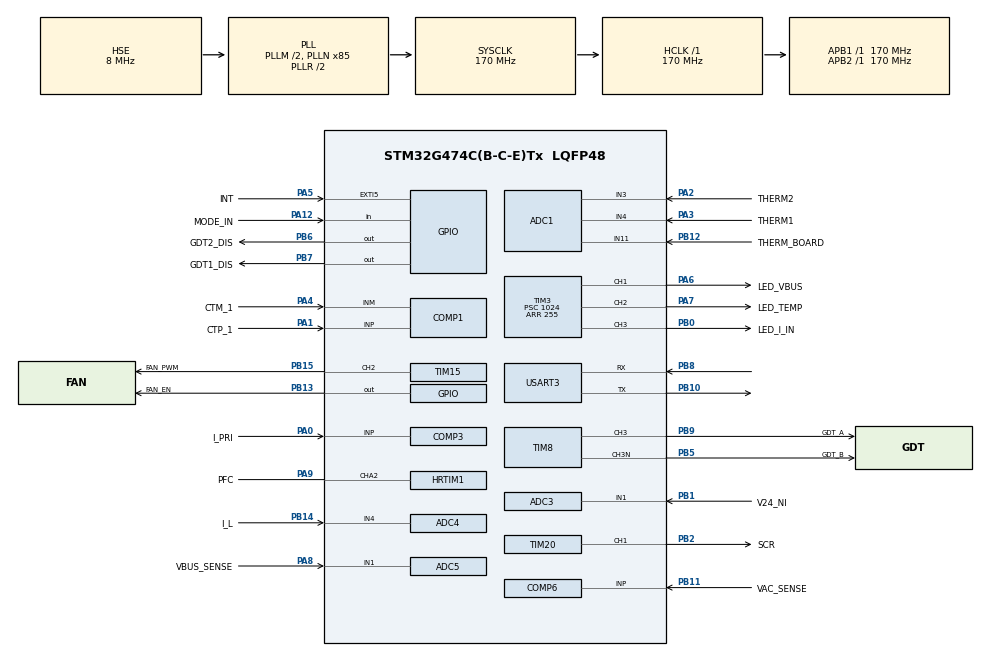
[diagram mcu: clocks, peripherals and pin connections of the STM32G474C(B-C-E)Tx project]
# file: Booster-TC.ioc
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ADC1.Channel-1\#ChannelRegularConversion=ADC_CHANNEL_3
ADC1.Channel-2\#ChannelRegularConversion=ADC_CHANNEL_4
ADC1.Channel-3\#ChannelRegularConversion=ADC_CHANNEL_11
ADC1.Channel-4\#ChannelRegularConversion=ADC_CHANNEL_VREFINT
ADC1.ClockPrescaler=ADC_CLOCK_SYNC_PCLK_DIV4
ADC1.EOCSelection=ADC_EOC_SEQ_CONV
ADC1.ExternalTrigConv=ADC_EXTERNALTRIG_T6_TRGO
ADC1.Mode=ADC_MODE_INDEPENDENT
ADC1.NbrOfConversion=4
ADC1.NbrOfConversionFlag=1
ADC1.OffsetNumber-1\#ChannelRegularConversion=ADC_OFFSET_NONE
ADC1.OffsetNumber-2\#ChannelRegularConversion=ADC_OFFSET_NONE
ADC1.OffsetNumber-3\#ChannelRegularConversion=ADC_OFFSET_NONE
ADC1.OffsetNumber-4\#ChannelRegularConversion=ADC_OFFSET_NONE
ADC1.OversamplingMode=ENABLE
ADC1.Rank-1\#ChannelRegularConversion=1
ADC1.Rank-2\#ChannelRegularConversion=2
ADC1.Rank-3\#ChannelRegularConversion=3
ADC1.Rank-4\#ChannelRegularConversion=4
ADC1.Ratio=ADC_OVERSAMPLING_RATIO_2
ADC1.RightBitShift=ADC_RIGHTBITSHIFT_1
ADC1.SamplingTime-1\#ChannelRegularConversion=ADC_SAMPLETIME_2CYCLES_5
ADC1.SamplingTime-2\#ChannelRegularConversion=ADC_SAMPLETIME_2CYCLES_5
ADC1.SamplingTime-3\#ChannelRegularConversion=ADC_SAMPLETIME_2CYCLES_5
ADC1.SamplingTime-4\#ChannelRegularConversion=ADC_SAMPLETIME_2CYCLES_5
ADC1.master=1
ADC2.Channel-2\#ChannelRegularConversion=ADC_CHANNEL_14
ADC2.ExternalTrigConv=ADC_EXTERNALTRIG_HRTIM_TRG3
ADC2.NbrOfConversionFlag=1
ADC2.OffsetNumber-2\#ChannelRegularConversion=ADC_OFFSET_NONE
ADC2.Rank-2\#ChannelRegularConversion=1
ADC2.SamplingTime-2\#ChannelRegularConversion=ADC_SAMPLETIME_2CYCLES_5
ADC3.Channel-1\#ChannelRegularConversion=ADC_CHANNEL_1
ADC3.NbrOfConversion=1
ADC3.NbrOfConversionFlag=1
ADC3.OffsetNumber-1\#ChannelRegularConversion=ADC_OFFSET_NONE
ADC3.Rank-1\#ChannelRegularConversion=1
ADC3.SamplingTime-1\#ChannelRegularConversion=ADC_SAMPLETIME_2CYCLES_5
ADC3.master=1
ADC4.Channel-1\#ChannelRegularConversion=ADC_CHANNEL_4
ADC4.ExternalTrigConv=ADC_EXTERNALTRIG_HRTIM_TRG3
ADC4.NbrOfConversionFlag=1
ADC4.OffsetNumber-1\#ChannelRegularConversion=ADC_OFFSET_NONE
ADC4.OversamplingMode=ENABLE
ADC4.Rank-1\#ChannelRegularConversion=1
ADC4.RightBitShift=ADC_RIGHTBITSHIFT_1
ADC4.SamplingTime-1\#ChannelRegularConversion=ADC_SAMPLETIME_2CYCLES_5
ADC5.Channel-1\#ChannelRegularConversion=ADC_CHANNEL_1
ADC5.ExternalTrigConv=ADC_EXTERNALTRIG_HRTIM_TRG1
ADC5.NbrOfConversionFlag=1
ADC5.OffsetNumber-1\#ChannelRegularConversion=ADC_OFFSET_NONE
ADC5.Rank-1\#ChannelRegularConversion=1
ADC5.SamplingTime-1\#ChannelRegularConversion=ADC_SAMPLETIME_2CYCLES_5
COMP1.TriggerMode=COMP_TRIGGERMODE_NONE
COMP3.TriggerMode=COMP_TRIGGERMODE_IT_RISING_FALLING
COMP6.Hysteresis=COMP_HYSTERESIS_NONE
COMP6.TriggerMode=COMP_TRIGGERMODE_IT_FALLING
DAC4.DAC_Channel-DAC_OUT2_Int=DAC_CHANNEL_2
Dma.ADC1.0.Direction=DMA_PERIPH_TO_MEMORY
Dma.ADC1.0.EventEnable=DISABLE
Dma.ADC1.0.Instance=DMA1_Channel1
Dma.ADC1.0.MemDataAlignment=DMA_MDATAALIGN_HALFWORD
Dma.ADC1.0.MemInc=DMA_MINC_ENABLE
Dma.ADC1.0.Mode=DMA_NORMAL
Dma.ADC1.0.PeriphDataAlignment=DMA_PDATAALIGN_HALFWORD
Dma.ADC1.0.PeriphInc=DMA_PINC_DISABLE
Dma.ADC1.0.Polarity=HAL_DMAMUX_REQ_GEN_RISING
Dma.ADC1.0.Priority=DMA_PRIORITY_LOW
Dma.ADC1.0.RequestNumber=1
Dma.ADC1.0.SignalID=NONE
Dma.ADC1.0.SyncEnable=DISABLE
Dma.ADC1.0.SyncPolarity=HAL_DMAMUX_SYNC_NO_EVENT
Dma.ADC1.0.SyncRequestNumber=1
Dma.ADC1.0.SyncSignalID=NONE
Dma.ADC2.1.Direction=DMA_PERIPH_TO_MEMORY
Dma.ADC2.1.EventEnable=DISABLE
Dma.ADC2.1.Instance=DMA2_Channel1
Dma.ADC2.1.MemDataAlignment=DMA_MDATAALIGN_HALFWORD
Dma.ADC2.1.MemInc=DMA_MINC_ENABLE
Dma.ADC2.1.Mode=DMA_NORMAL
Dma.ADC2.1.PeriphDataAlignment=DMA_PDATAALIGN_HALFWORD
Dma.ADC2.1.PeriphInc=DMA_PINC_DISABLE
Dma.ADC2.1.Polarity=HAL_DMAMUX_REQ_GEN_RISING
Dma.ADC2.1.Priority=DMA_PRIORITY_VERY_HIGH
Dma.ADC2.1.RequestNumber=1
Dma.ADC2.1.SignalID=NONE
Dma.ADC2.1.SyncEnable=DISABLE
Dma.ADC2.1.SyncPolarity=HAL_DMAMUX_SYNC_NO_EVENT
Dma.ADC2.1.SyncRequestNumber=1
Dma.ADC2.1.SyncSignalID=NONE
Dma.ADC4.2.Direction=DMA_PERIPH_TO_MEMORY
Dma.ADC4.2.EventEnable=DISABLE
Dma.ADC4.2.Instance=DMA2_Channel2
Dma.ADC4.2.MemDataAlignment=DMA_MDATAALIGN_HALFWORD
Dma.ADC4.2.MemInc=DMA_MINC_ENABLE
Dma.ADC4.2.Mode=DMA_NORMAL
Dma.ADC4.2.PeriphDataAlignment=DMA_PDATAALIGN_HALFWORD
Dma.ADC4.2.PeriphInc=DMA_PINC_DISABLE
Dma.ADC4.2.Polarity=HAL_DMAMUX_REQ_GEN_RISING
Dma.ADC4.2.Priority=DMA_PRIORITY_VERY_HIGH
Dma.ADC4.2.RequestNumber=1
Dma.ADC4.2.SignalID=NONE
Dma.ADC4.2.SyncEnable=DISABLE
Dma.ADC4.2.SyncPolarity=HAL_DMAMUX_SYNC_NO_EVENT
Dma.ADC4.2.SyncRequestNumber=1
Dma.ADC4.2.SyncSignalID=NONE
Dma.ADC5.3.Direction=DMA_PERIPH_TO_MEMORY
Dma.ADC5.3.EventEnable=DISABLE
Dma.ADC5.3.Instance=DMA1_Channel2
Dma.ADC5.3.MemDataAlignment=DMA_MDATAALIGN_HALFWORD
Dma.ADC5.3.MemInc=DMA_MINC_ENABLE
Dma.ADC5.3.Mode=DMA_NORMAL
Dma.ADC5.3.PeriphDataAlignment=DMA_PDATAALIGN_HALFWORD
Dma.ADC5.3.PeriphInc=DMA_PINC_DISABLE
Dma.ADC5.3.Polarity=HAL_DMAMUX_REQ_GEN_RISING
Dma.ADC5.3.Priority=DMA_PRIORITY_LOW
Dma.ADC5.3.RequestNumber=1
Dma.ADC5.3.SignalID=NONE
Dma.ADC5.3.SyncEnable=DISABLE
Dma.ADC5.3.SyncPolarity=HAL_DMAMUX_SYNC_NO_EVENT
Dma.ADC5.3.SyncRequestNumber=1
Dma.ADC5.3.SyncSignalID=NONE
Dma.Request0=ADC1
Dma.Request1=ADC2
Dma.Request2=ADC4
Dma.Request3=ADC5
HRTIM1.ADCTrigger1_Source1=HRTIM_ADCTRIGGEREVENT13_TIMERD_PERIOD
HRTIM1.ADCTrigger3_Source1=HRTIM_ADCTRIGGEREVENT13_TIMERA_CMP3
HRTIM1.ADCTrigger_Id1=HRTIM_ADCTRIGGER_1
HRTIM1.ADCTrigger_Id2=__NULL
HRTIM1.ADCTrigger_Id3=HRTIM_ADCTRIGGER_3
HRTIM1.CompareUnit1-Output_TA2=HRTIM_COMPAREUNIT_1
HRTIM1.CompareUnit2-Output_TA2=__NULL
HRTIM1.CompareUnit3-Output_TA2=HRTIM_COMPAREUNIT_3
HRTIM1.Event_EEV1=__NULL
HRTIM1.Event_EEV2=__NULL
HRTIM1.Event_EEV3=__NULL
HRTIM1.Event_EEV4=__NULL
HRTIM1.Event_EEV5=HRTIM_EVENT_5
HRTIM1.Event_EEV7=__NULL
HRTIM1.FastMode_EEV5=HRTIM_EVENTFASTMODE_ENABLE
HRTIM1.Fault_Line1=__NULL
HRTIM1.NumberADCTriggerSource1=1
HRTIM1.NumberADCTriggerSource3=1
HRTIM1.NumberFaultEnable-Output_TA2=0
HRTIM1.NumberResetSource2-Output_TA2=2
HRTIM1.NumberSetSource2-Output_TA2=1
HRTIM1.ORingUpdateSource_ADCTrigger1=HRTIM_ADCTRIGGERUPDATE_TIMER_D
HRTIM1.Periode_TA=0xB115
HRTIM1.Periode_TD=0xDD5A
HRTIM1.PrescalerRatio_TA=HRTIM_PRESCALERRATIO_MUL16
HRTIM1.PrescalerRatio_TD=HRTIM_PRESCALERRATIO_MUL2
HRTIM1.ResetOutput2_Source1-Output_TA2=HRTIM_OUTPUTRESET_TIMCMP1
HRTIM1.ResetOutput2_Source2-Output_TA2=HRTIM_OUTPUTSET_EEV_5
HRTIM1.SetOutput2_Source1-Output_TA2=HRTIM_OUTPUTSET_TIMPER
HRTIM1.Source_EEV5=HRTIM_EEV5SRC_COMP7_OUT
HRTIM1.UpDownMode-Output_TA2=HRTIM_TIMERUPDOWNMODE_UP
Mcu.Family=STM32G4
Mcu.Name=STM32G474C(B-C-E)Tx
Mcu.Package=LQFP48
NVIC.ADC1_2_IRQn=true\:0\:0\:false\:false\:false\:true\:true\:true
NVIC.ADC4_IRQn=true\:0\:0\:false\:false\:false\:true\:true\:true
NVIC.ADC5_IRQn=true\:0\:0\:false\:false\:false\:true\:true\:true
NVIC.COMP1_2_3_IRQn=true\:0\:0\:false\:false\:true\:false\:true\:true
NVIC.COMP4_5_6_IRQn=true\:0\:0\:false\:false\:true\:false\:true\:true
NVIC.DMA1_Channel1_IRQn=true\:0\:0\:false\:false\:true\:false\:true\:true
NVIC.DMA1_Channel2_IRQn=true\:0\:0\:false\:false\:true\:false\:true\:true
NVIC.DMA2_Channel1_IRQn=true\:0\:0\:false\:false\:true\:false\:true\:true
NVIC.DMA2_Channel2_IRQn=true\:0\:0\:false\:false\:true\:false\:true\:true
NVIC.EXTI9_5_IRQn=true\:0\:0\:false\:false\:true\:true\:true\:true
NVIC.FMAC_IRQn=true\:0\:0\:false\:false\:true\:true\:true\:true
NVIC.PriorityGroup=NVIC_PRIORITYGROUP_4
NVIC.TIM1_CC_IRQn=true\:0\:0\:false\:false\:false\:true\:true\:true
NVIC.TIM1_TRG_COM_TIM17_IRQn=true\:0\:0\:false\:false\:true\:true\:true\:true
NVIC.TIM6_DAC_IRQn=true\:0\:0\:false\:false\:false\:true\:true\:true
NVIC.TIM7_DAC_IRQn=true\:0\:0\:false\:false\:false\:true\:true\:true
PA0.GPIO_Label=I_PRI
PA0.Mode=INP
PA0.Signal=COMP3_INP
PA1.GPIO_Label=CTP_1
PA1.Mode=INP
PA1.Signal=COMP1_INP
PA12.GPIO_Label=MODE_IN
PA12.GPIO_PuPd=GPIO_NOPULL
PA12.Signal=GPIO_Input
PA13.GPIO_Label=TMS
PA13.Mode=JTAG_4_pins
PA13.Signal=SYS_JTMS-SWDIO
PA14.GPIO_Label=TCK
PA14.Mode=JTAG_4_pins
PA14.Signal=SYS_JTCK-SWCLK
PA15.Mode=JTAG_4_pins
PA15.Signal=SYS_JTDI
PA2.GPIO_Label=THERM2
PA2.Mode=IN3-Single-Ended
PA2.Signal=ADC1_IN3
PA3.GPIO_Label=THERM1
PA3.Mode=IN4-Single-Ended
PA3.Signal=ADC1_IN4
PA4.GPIO_Label=CTM_1
PA4.Mode=INM
PA4.Signal=COMP1_INM
PA5.GPIO_Label=INT
PA5.GPIO_ModeDefaultEXTI=GPIO_MODE_IT_RISING_FALLING
PA5.Signal=GPXTI5
PA6.GPIO_Label=LED_VBUS
PA6.Signal=S_TIM3_CH1
PA7.GPIO_Label=LED_TEMP
PA7.Signal=S_TIM3_CH2
PA8.GPIO_Label=VBUS_SENSE
PA8.Mode=IN1-Single-Ended
PA8.Signal=ADC5_IN1
PA9.GPIO_Label=PFC
PA9.GPIO_PuPd=GPIO_PULLDOWN
PA9.Mode=Output_TA2
PA9.Signal=HRTIM1_CHA2
PB0.GPIO_Label=LED_I_IN
PB0.Signal=S_TIM3_CH3
PB1.GPIO_Label=V24_NI
PB1.Mode=IN1-Single-Ended
PB1.Signal=ADC3_IN1
PB10.Mode=Asynchronous
PB10.Signal=USART3_TX
PB11.GPIO_Label=VAC_SENSE
PB11.Signal=SharedAnalog_PB11
PB12.GPIO_Label=THERM_BOARD
PB12.Mode=IN11-Single-Ended
PB12.Signal=ADC1_IN11
PB13.GPIO_Label=FAN_EN
PB13.Signal=GPIO_Output
PB14.GPIO_Label=I_L
PB14.Signal=SharedAnalog_PB14
PB15.GPIO_Label=FAN_PWM
PB15.Signal=S_TIM15_CH2
PB2.GPIO_Label=SCR
PB2.Signal=S_TIM20_CH1
PB3.Mode=JTAG_4_pins
PB3.Signal=SYS_JTDO-SWO
PB4.Signal=SYS_JTRST
PB5.GPIO_Label=GDT_B
PB5.Mode=PWM Generation3 CH3 CH3N
PB5.Signal=TIM8_CH3N
PB6.GPIO_Label=GDT2_DIS
PB6.GPIO_Speed=GPIO_SPEED_FREQ_VERY_HIGH
PB6.Signal=GPIO_Output
PB7.GPIO_Label=GDT1_DIS
PB7.GPIO_Speed=GPIO_SPEED_FREQ_VERY_HIGH
PB7.Signal=GPIO_Output
PB8-BOOT0.Mode=Asynchronous
PB8-BOOT0.Signal=USART3_RX
PB9.GPIO_Label=GDT_A
PB9.Signal=S_TIM8_CH3
PF0-OSC_IN.Mode=HSE-External-Oscillator
PF0-OSC_IN.Signal=RCC_OSC_IN
PF1-OSC_OUT.Mode=HSE-External-Oscillator
PF1-OSC_OUT.Signal=RCC_OSC_OUT
ProjectManager.HeapSize=0x200
ProjectManager.StackSize=0x400
ProjectManager.TargetToolchain=STM32CubeIDE
RCC.ADC12Freq_Value=170000000
RCC.ADC345Freq_Value=170000000
RCC.AHBFreq_Value=170000000
RCC.APB1Freq_Value=170000000
RCC.APB1TimFreq_Value=170000000
RCC.APB2Freq_Value=170000000
RCC.APB2TimFreq_Value=170000000
RCC.CortexFreq_Value=170000000
RCC.EXTERNAL_CLOCK_VALUE=12288000
RCC.HCLKFreq_Value=170000000
RCC.HSE_VALUE=8000000
RCC.HSI48_VALUE=48000000
RCC.HSI_VALUE=16000000
RCC.LSE_VALUE=32768
RCC.PLLM=RCC_PLLM_DIV2
RCC.PLLN=85
RCC.PLLSourceVirtual=RCC_PLLSOURCE_HSE
RCC.SYSCLKFreq_VALUE=170000000
RCC.SYSCLKSource=RCC_SYSCLKSOURCE_PLLCLK
RCC.USBFreq_Value=170000000
RCC.VCOOutputFreq_Value=340000000
SH.S_TIM15_CH2.0=TIM15_CH2,PWM Generation2 CH2
SH.S_TIM20_CH1.0=TIM20_CH1,PWM Generation1 CH1
SH.S_TIM3_CH1.0=TIM3_CH1,PWM Generation1 CH1
SH.S_TIM3_CH2.0=TIM3_CH2,PWM Generation2 CH2
SH.S_TIM3_CH3.0=TIM3_CH3,PWM Generation3 CH3
SH.S_TIM8_CH3.0=TIM8_CH3,PWM Generation3 CH3 CH3N
SH.SharedAnalog_PB11.0=COMP6_INP,INP
SH.SharedAnalog_PB11.1=ADC2_IN14,IN14-Single-Ended
SH.SharedAnalog_PB14.0=ADC4_IN4,IN4-Single-Ended
SH.SharedAnalog_PB14.1=COMP7_INP,INP
SYS.VoltageScaling=SYSCFG_VREFBUF_VOLTAGE_SCALE2
TIM1.Channel-Input_Capture1_from_TI1_REMAP_TIM1=TIM_CHANNEL_1
TIM1.Channel-PWM\ Generation2\ No\ Output=TIM_CHANNEL_2
TIM1.TIM1_ETR_REMAP-TriggerSource_ETR_Remap_TIM1=TIM_TIM1_ETR_COMP1
TIM1.TIM_MasterOutputTrigger=TIM_TRGO_OC2REF
TIM15.Channel-PWM\ Generation2\ CH2=TIM_CHANNEL_2
TIM20.Channel-PWM\ Generation1\ CH1=TIM_CHANNEL_1
TIM20.OCMode_PWM-PWM\ Generation1\ CH1=TIM_OCMODE_PWM2
TIM20.Prescaler=170
TIM20.TIM20_ETR_REMAP-TriggerSource_ETR_Remap_TIM20=TIM_TIM20_ETR_COMP6
TIM3.Channel-PWM\ Generation1\ CH1=TIM_CHANNEL_1
TIM3.Channel-PWM\ Generation2\ CH2=TIM_CHANNEL_2
TIM3.Channel-PWM\ Generation3\ CH3=TIM_CHANNEL_3
TIM3.PeriodNoDither=255
TIM3.Prescaler=1024
TIM6.PeriodNoDither=10000
TIM6.Prescaler=170
TIM6.TIM_MasterOutputTrigger=TIM_TRGO_UPDATE
TIM7.PeriodNoDither=5000
TIM7.Prescaler=17000
TIM7.TIM_MasterOutputTrigger=TIM_TRGO_UPDATE
TIM8.Channel-PWM\ Generation3\ CH3\ CH3N=TIM_CHANNEL_3
TIM8.DeadTime=9
TIM8.DeadTimePreload=DISABLE
USART3.VirtualMode-Asynchronous=VM_ASYNC
VP_ADC1_Vref_Input.Mode=IN-Vrefint
VP_COMP3_VS_DAC3OUT1.Mode=INM_DAC3OUT1
VP_COMP6_VS_DAC4OUT2.Mode=INM_DAC4OUT2
VP_COMP7_VS_DAC2OUT1.Mode=INM_DAC2OUT1
VP_DAC2_VS_DACI1.Mode=DAC_OUT1_Int
VP_DAC3_VS_DACI1.Mode=DAC_OUT1_Int
VP_DAC4_VS_DACI2.Mode=DAC_OUT2_Int
VP_FMAC_VS_FMAC.Mode=FMAC_Activate
VP_HRTIM1_VS_hrtimTimerDNoOutput.Mode=No_output_TD
VP_SYS_VS_DBSignals.Mode=DisableDeadBatterySignals
VP_TIM1_VS_ClockSourceINT.Mode=Internal
VP_TIM1_VS_ControllerModeReset.Mode=Reset Mode
VP_TIM1_VS_NoETR.Mode=TriggerSource_ETR_Remap_TIM1
VP_TIM1_VS_NoInput1.Mode=Input_Capture1_from_TI1_REMAP_TIM1
VP_TIM1_VS_no_output2.Mode=PWM Generation2 No Output
VP_TIM20_VS_ClockSourceINT.Mode=Internal
VP_TIM20_VS_ControllerModeCombinedResetTrigger.Mode=Combined_Reset_Trigger_Mode
VP_TIM20_VS_NoETR.Mode=TriggerSource_ETR_Remap_TIM20
VP_TIM20_VS_OPM.Mode=OPM_bit
VP_TIM3_VS_ClockSourceINT.Mode=Internal
VP_TIM6_VS_ClockSourceINT.Mode=Enable_Timer
VP_TIM7_VS_ClockSourceINT.Mode=Enable_Timer
VP_TIM8_VS_ClockSourceINT.Mode=Internal
VP_TIM8_VS_ClockSourceITR.Mode=TriggerSource_ITR0
VP_TIM8_VS_ControllerModeReset.Mode=Reset Mode
VREF+.GPIO_Label=VREF
VREF+.Mode=InternalMode
VREF+.Signal=VREFBUF_OUT
board=custom

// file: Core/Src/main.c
/* USER CODE BEGIN Header */
/**
  ******************************************************************************
  * @file           : main.c
  * @brief          : Main program body
  ******************************************************************************
  * @attention
  *
  * Copyright (c) 2024 STMicroelectronics.
  * All rights reserved.
  *
  * This software is licensed under terms that can be found in the LICENSE file
  * in the root directory of this software component.
  * If no LICENSE file comes with this software, it is provided AS-IS.
  *
  ******************************************************************************
  */
/* USER CODE END Header */
#include "main.h"

/* USER CODE BEGIN Includes */
#include "booster_tc.h"
/* USER CODE END Includes */

ADC_HandleTypeDef hadc1;
ADC_HandleTypeDef hadc2;
ADC_HandleTypeDef hadc3;
ADC_HandleTypeDef hadc4;
ADC_HandleTypeDef hadc5;
DMA_HandleTypeDef hdma_adc1;
DMA_HandleTypeDef hdma_adc2;
DMA_HandleTypeDef hdma_adc4;
DMA_HandleTypeDef hdma_adc5;

COMP_HandleTypeDef hcomp1;
COMP_HandleTypeDef hcomp3;
COMP_HandleTypeDef hcomp6;
COMP_HandleTypeDef hcomp7;

DAC_HandleTypeDef hdac2;
DAC_HandleTypeDef hdac3;
DAC_HandleTypeDef hdac4;

FMAC_HandleTypeDef hfmac;

HRTIM_HandleTypeDef hhrtim1;

TIM_HandleTypeDef htim1;
TIM_HandleTypeDef htim3;
TIM_HandleTypeDef htim6;
TIM_HandleTypeDef htim7;
TIM_HandleTypeDef htim8;
TIM_HandleTypeDef htim15;
TIM_HandleTypeDef htim20;

UART_HandleTypeDef huart3;

void SystemClock_Config(void);
static void MX_GPIO_Init(void);
static void MX_DMA_Init(void);
static void MX_ADC1_Init(void);
static void MX_ADC2_Init(void);
static void MX_ADC4_Init(void);
static void MX_ADC5_Init(void);
static void MX_COMP1_Init(void);
static void MX_COMP3_Init(void);
static void MX_COMP6_Init(void);
static void MX_DAC3_Init(void);
static void MX_HRTIM1_Init(void);
static void MX_TIM3_Init(void);
static void MX_TIM8_Init(void);
static void MX_COMP7_Init(void);
static void MX_DAC2_Init(void);
static void MX_FMAC_Init(void);
static void MX_TIM20_Init(void);
static void MX_TIM6_Init(void);
static void MX_TIM7_Init(void);
static void MX_TIM1_Init(void);
static void MX_USART3_UART_Init(void);
static void MX_ADC3_Init(void);
static void MX_TIM15_Init(void);
static void MX_DAC4_Init(void);

int main(void)
{

  /* MCU Configuration--------------------------------------------------------*/

  /* Reset of all peripherals, Initializes the Flash interface and the Systick. */
  HAL_Init();

  /* Configure the system clock */
  SystemClock_Config();

  /* Initialize all configured peripherals */
  MX_GPIO_Init();
  MX_DMA_Init();
  MX_ADC1_Init();
  MX_ADC2_Init();
  MX_ADC4_Init();
  MX_ADC5_Init();
  MX_COMP1_Init();
  MX_COMP3_Init();
  MX_COMP6_Init();
  MX_DAC3_Init();
  MX_HRTIM1_Init();
  MX_TIM3_Init();
  MX_TIM8_Init();
  MX_COMP7_Init();
  MX_DAC2_Init();
  MX_FMAC_Init();
  MX_TIM20_Init();
  MX_TIM6_Init();
  MX_TIM7_Init();
  MX_TIM1_Init();
  MX_USART3_UART_Init();
  MX_ADC3_Init();
  MX_TIM15_Init();
  MX_DAC4_Init();
  /* USER CODE BEGIN 2 */
  booster_init();
  /* USER CODE END 2 */

  /* Infinite loop */
  while (1)
  {

    /* USER CODE BEGIN 3 */
	  booster_loop();
  }
  /* USER CODE END 3 */
}

void SystemClock_Config(void)
{
  RCC_OscInitTypeDef RCC_OscInitStruct = {0};
  RCC_ClkInitTypeDef RCC_ClkInitStruct = {0};

  /** Configure the main internal regulator output voltage
  */
  HAL_PWREx_ControlVoltageScaling(PWR_REGULATOR_VOLTAGE_SCALE1_BOOST);

  /** Initializes the RCC Oscillators according to the specified parameters
  * in the RCC_OscInitTypeDef structure.
  */
  RCC_OscInitStruct.OscillatorType = RCC_OSCILLATORTYPE_HSE;
  RCC_OscInitStruct.HSEState = RCC_HSE_ON;
  RCC_OscInitStruct.PLL.PLLState = RCC_PLL_ON;
  RCC_OscInitStruct.PLL.PLLSource = RCC_PLLSOURCE_HSE;
  RCC_OscInitStruct.PLL.PLLM = RCC_PLLM_DIV2;
  RCC_OscInitStruct.PLL.PLLN = 85;
  RCC_OscInitStruct.PLL.PLLP = RCC_PLLP_DIV2;
  RCC_OscInitStruct.PLL.PLLQ = RCC_PLLQ_DIV2;
  RCC_OscInitStruct.PLL.PLLR = RCC_PLLR_DIV2;
  if (HAL_RCC_OscConfig(&RCC_OscInitStruct) != HAL_OK)
  {
    Error_Handler();
  }

  /** Initializes the CPU, AHB and APB buses clocks
  */
  RCC_ClkInitStruct.ClockType = RCC_CLOCKTYPE_HCLK|RCC_CLOCKTYPE_SYSCLK
                              |RCC_CLOCKTYPE_PCLK1|RCC_CLOCKTYPE_PCLK2;
  RCC_ClkInitStruct.SYSCLKSource = RCC_SYSCLKSOURCE_PLLCLK;
  RCC_ClkInitStruct.AHBCLKDivider = RCC_SYSCLK_DIV1;
  RCC_ClkInitStruct.APB1CLKDivider = RCC_HCLK_DIV1;
  RCC_ClkInitStruct.APB2CLKDivider = RCC_HCLK_DIV1;

  if (HAL_RCC_ClockConfig(&RCC_ClkInitStruct, FLASH_LATENCY_4) != HAL_OK)
  {
    Error_Handler();
  }
}

static void MX_ADC1_Init(void)
{

  ADC_MultiModeTypeDef multimode = {0};
  ADC_ChannelConfTypeDef sConfig = {0};

  /** Common config
  */
  hadc1.Instance = ADC1;
  hadc1.Init.ClockPrescaler = ADC_CLOCK_SYNC_PCLK_DIV4;
  hadc1.Init.Resolution = ADC_RESOLUTION_12B;
  hadc1.Init.DataAlign = ADC_DATAALIGN_RIGHT;
  hadc1.Init.GainCompensation = 0;
  hadc1.Init.ScanConvMode = ADC_SCAN_ENABLE;
  hadc1.Init.EOCSelection = ADC_EOC_SEQ_CONV;
  hadc1.Init.LowPowerAutoWait = DISABLE;
  hadc1.Init.ContinuousConvMode = DISABLE;
  hadc1.Init.NbrOfConversion = 4;
  hadc1.Init.DiscontinuousConvMode = DISABLE;
  hadc1.Init.ExternalTrigConv = ADC_EXTERNALTRIG_T6_TRGO;
  hadc1.Init.ExternalTrigConvEdge = ADC_EXTERNALTRIGCONVEDGE_RISING;
  hadc1.Init.DMAContinuousRequests = DISABLE;
  hadc1.Init.Overrun = ADC_OVR_DATA_PRESERVED;
  hadc1.Init.OversamplingMode = ENABLE;
  hadc1.Init.Oversampling.Ratio = ADC_OVERSAMPLING_RATIO_2;
  hadc1.Init.Oversampling.RightBitShift = ADC_RIGHTBITSHIFT_1;
  hadc1.Init.Oversampling.TriggeredMode = ADC_TRIGGEREDMODE_SINGLE_TRIGGER;
  hadc1.Init.Oversampling.OversamplingStopReset = ADC_REGOVERSAMPLING_CONTINUED_MODE;
  if (HAL_ADC_Init(&hadc1) != HAL_OK)
  {
    Error_Handler();
  }

  /** Configure the ADC multi-mode
  */
  multimode.Mode = ADC_MODE_INDEPENDENT;
  if (HAL_ADCEx_MultiModeConfigChannel(&hadc1, &multimode) != HAL_OK)
  {
    Error_Handler();
  }

  /** Configure Regular Channel
  */
  sConfig.Channel = ADC_CHANNEL_3;
  sConfig.Rank = ADC_REGULAR_RANK_1;
  sConfig.SamplingTime = ADC_SAMPLETIME_2CYCLES_5;
  sConfig.SingleDiff = ADC_SINGLE_ENDED;
  sConfig.OffsetNumber = ADC_OFFSET_NONE;
  sConfig.Offset = 0;
  if (HAL_ADC_ConfigChannel(&hadc1, &sConfig) != HAL_OK)
  {
    Error_Handler();
  }

  /** Configure Regular Channel
  */
  sConfig.Channel = ADC_CHANNEL_4;
  sConfig.Rank = ADC_REGULAR_RANK_2;
  if (HAL_ADC_ConfigChannel(&hadc1, &sConfig) != HAL_OK)
  {
    Error_Handler();
  }

  /** Configure Regular Channel
  */
  sConfig.Channel = ADC_CHANNEL_11;
  sConfig.Rank = ADC_REGULAR_RANK_3;
  if (HAL_ADC_ConfigChannel(&hadc1, &sConfig) != HAL_OK)
  {
    Error_Handler();
  }

  /** Configure Regular Channel
  */
  sConfig.Channel = ADC_CHANNEL_VREFINT;
  sConfig.Rank = ADC_REGULAR_RANK_4;
  if (HAL_ADC_ConfigChannel(&hadc1, &sConfig) != HAL_OK)
  {
    Error_Handler();
  }

}

static void MX_ADC2_Init(void)
{

  ADC_ChannelConfTypeDef sConfig = {0};

  /** Common config
  */
  hadc2.Instance = ADC2;
  hadc2.Init.ClockPrescaler = ADC_CLOCK_SYNC_PCLK_DIV4;
  hadc2.Init.Resolution = ADC_RESOLUTION_12B;
  hadc2.Init.DataAlign = ADC_DATAALIGN_RIGHT;
  hadc2.Init.GainCompensation = 0;
  hadc2.Init.ScanConvMode = ADC_SCAN_DISABLE;
  hadc2.Init.EOCSelection = ADC_EOC_SINGLE_CONV;
  hadc2.Init.LowPowerAutoWait = DISABLE;
  hadc2.Init.ContinuousConvMode = DISABLE;
  hadc2.Init.NbrOfConversion = 1;
  hadc2.Init.DiscontinuousConvMode = DISABLE;
  hadc2.Init.ExternalTrigConv = ADC_EXTERNALTRIG_HRTIM_TRG3;
  hadc2.Init.ExternalTrigConvEdge = ADC_EXTERNALTRIGCONVEDGE_RISING;
  hadc2.Init.DMAContinuousRequests = DISABLE;
  hadc2.Init.Overrun = ADC_OVR_DATA_PRESERVED;
  hadc2.Init.OversamplingMode = DISABLE;
  if (HAL_ADC_Init(&hadc2) != HAL_OK)
  {
    Error_Handler();
  }

  /** Configure Regular Channel
  */
  sConfig.Channel = ADC_CHANNEL_14;
  sConfig.Rank = ADC_REGULAR_RANK_1;
  sConfig.SamplingTime = ADC_SAMPLETIME_2CYCLES_5;
  sConfig.SingleDiff = ADC_SINGLE_ENDED;
  sConfig.OffsetNumber = ADC_OFFSET_NONE;
  sConfig.Offset = 0;
  if (HAL_ADC_ConfigChannel(&hadc2, &sConfig) != HAL_OK)
  {
    Error_Handler();
  }

}

static void MX_ADC3_Init(void)
{

  ADC_MultiModeTypeDef multimode = {0};
  ADC_ChannelConfTypeDef sConfig = {0};

  /** Common config
  */
  hadc3.Instance = ADC3;
  hadc3.Init.ClockPrescaler = ADC_CLOCK_SYNC_PCLK_DIV4;
  hadc3.Init.Resolution = ADC_RESOLUTION_12B;
  hadc3.Init.DataAlign = ADC_DATAALIGN_RIGHT;
  hadc3.Init.GainCompensation = 0;
  hadc3.Init.ScanConvMode = ADC_SCAN_DISABLE;
  hadc3.Init.EOCSelection = ADC_EOC_SINGLE_CONV;
  hadc3.Init.LowPowerAutoWait = DISABLE;
  hadc3.Init.ContinuousConvMode = DISABLE;
  hadc3.Init.NbrOfConversion = 1;
  hadc3.Init.DiscontinuousConvMode = DISABLE;
  hadc3.Init.ExternalTrigConv = ADC_SOFTWARE_START;
  hadc3.Init.ExternalTrigConvEdge = ADC_EXTERNALTRIGCONVEDGE_NONE;
  hadc3.Init.DMAContinuousRequests = DISABLE;
  hadc3.Init.Overrun = ADC_OVR_DATA_PRESERVED;
  hadc3.Init.OversamplingMode = DISABLE;
  if (HAL_ADC_Init(&hadc3) != HAL_OK)
  {
    Error_Handler();
  }

  /** Configure the ADC multi-mode
  */
  multimode.Mode = ADC_MODE_INDEPENDENT;
  if (HAL_ADCEx_MultiModeConfigChannel(&hadc3, &multimode) != HAL_OK)
  {
    Error_Handler();
  }

  /** Configure Regular Channel
  */
  sConfig.Channel = ADC_CHANNEL_1;
  sConfig.Rank = ADC_REGULAR_RANK_1;
  sConfig.SamplingTime = ADC_SAMPLETIME_2CYCLES_5;
  sConfig.SingleDiff = ADC_SINGLE_ENDED;
  sConfig.OffsetNumber = ADC_OFFSET_NONE;
  sConfig.Offset = 0;
  if (HAL_ADC_ConfigChannel(&hadc3, &sConfig) != HAL_OK)
  {
    Error_Handler();
  }

}

static void MX_ADC4_Init(void)
{

  ADC_ChannelConfTypeDef sConfig = {0};

  /** Common config
  */
  hadc4.Instance = ADC4;
  hadc4.Init.ClockPrescaler = ADC_CLOCK_SYNC_PCLK_DIV4;
  hadc4.Init.Resolution = ADC_RESOLUTION_12B;
  hadc4.Init.DataAlign = ADC_DATAALIGN_RIGHT;
  hadc4.Init.GainCompensation = 0;
  hadc4.Init.ScanConvMode = ADC_SCAN_DISABLE;
  hadc4.Init.EOCSelection = ADC_EOC_SINGLE_CONV;
  hadc4.Init.LowPowerAutoWait = DISABLE;
  hadc4.Init.ContinuousConvMode = DISABLE;
  hadc4.Init.NbrOfConversion = 1;
  hadc4.Init.DiscontinuousConvMode = DISABLE;
  hadc4.Init.ExternalTrigConv = ADC_EXTERNALTRIG_HRTIM_TRG3;
  hadc4.Init.ExternalTrigConvEdge = ADC_EXTERNALTRIGCONVEDGE_RISING;
  hadc4.Init.DMAContinuousRequests = DISABLE;
  hadc4.Init.Overrun = ADC_OVR_DATA_PRESERVED;
  hadc4.Init.OversamplingMode = ENABLE;
  hadc4.Init.Oversampling.Ratio = ADC_OVERSAMPLING_RATIO_2;
  hadc4.Init.Oversampling.RightBitShift = ADC_RIGHTBITSHIFT_1;
  hadc4.Init.Oversampling.TriggeredMode = ADC_TRIGGEREDMODE_SINGLE_TRIGGER;
  hadc4.Init.Oversampling.OversamplingStopReset = ADC_REGOVERSAMPLING_CONTINUED_MODE;
  if (HAL_ADC_Init(&hadc4) != HAL_OK)
  {
    Error_Handler();
  }

  /** Configure Regular Channel
  */
  sConfig.Channel = ADC_CHANNEL_4;
  sConfig.Rank = ADC_REGULAR_RANK_1;
  sConfig.SamplingTime = ADC_SAMPLETIME_2CYCLES_5;
  sConfig.SingleDiff = ADC_SINGLE_ENDED;
  sConfig.OffsetNumber = ADC_OFFSET_NONE;
  sConfig.Offset = 0;
  if (HAL_ADC_ConfigChannel(&hadc4, &sConfig) != HAL_OK)
  {
    Error_Handler();
  }

}

static void MX_ADC5_Init(void)
{

  ADC_ChannelConfTypeDef sConfig = {0};

  /** Common config
  */
  hadc5.Instance = ADC5;
  hadc5.Init.ClockPrescaler = ADC_CLOCK_SYNC_PCLK_DIV4;
  hadc5.Init.Resolution = ADC_RESOLUTION_12B;
  hadc5.Init.DataAlign = ADC_DATAALIGN_RIGHT;
  hadc5.Init.GainCompensation = 0;
  hadc5.Init.ScanConvMode = ADC_SCAN_DISABLE;
  hadc5.Init.EOCSelection = ADC_EOC_SINGLE_CONV;
  hadc5.Init.LowPowerAutoWait = DISABLE;
  hadc5.Init.ContinuousConvMode = DISABLE;
  hadc5.Init.NbrOfConversion = 1;
  hadc5.Init.DiscontinuousConvMode = DISABLE;
  hadc5.Init.ExternalTrigConv = ADC_EXTERNALTRIG_HRTIM_TRG1;
  hadc5.Init.ExternalTrigConvEdge = ADC_EXTERNALTRIGCONVEDGE_RISING;
  hadc5.Init.DMAContinuousRequests = DISABLE;
  hadc5.Init.Overrun = ADC_OVR_DATA_PRESERVED;
  hadc5.Init.OversamplingMode = DISABLE;
  if (HAL_ADC_Init(&hadc5) != HAL_OK)
  {
    Error_Handler();
  }

  /** Configure Regular Channel
  */
  sConfig.Channel = ADC_CHANNEL_1;
  sConfig.Rank = ADC_REGULAR_RANK_1;
  sConfig.SamplingTime = ADC_SAMPLETIME_2CYCLES_5;
  sConfig.SingleDiff = ADC_SINGLE_ENDED;
  sConfig.OffsetNumber = ADC_OFFSET_NONE;
  sConfig.Offset = 0;
  if (HAL_ADC_ConfigChannel(&hadc5, &sConfig) != HAL_OK)
  {
    Error_Handler();
  }

}

static void MX_COMP1_Init(void)
{

  hcomp1.Instance = COMP1;
  hcomp1.Init.InputPlus = COMP_INPUT_PLUS_IO1;
  hcomp1.Init.InputMinus = COMP_INPUT_MINUS_IO1;
  hcomp1.Init.OutputPol = COMP_OUTPUTPOL_NONINVERTED;
  hcomp1.Init.Hysteresis = COMP_HYSTERESIS_NONE;
  hcomp1.Init.BlankingSrce = COMP_BLANKINGSRC_NONE;
  hcomp1.Init.TriggerMode = COMP_TRIGGERMODE_NONE;
  if (HAL_COMP_Init(&hcomp1) != HAL_OK)
  {
    Error_Handler();
  }

}

static void MX_COMP3_Init(void)
{

  hcomp3.Instance = COMP3;
  hcomp3.Init.InputPlus = COMP_INPUT_PLUS_IO1;
  hcomp3.Init.InputMinus = COMP_INPUT_MINUS_DAC3_CH1;
  hcomp3.Init.OutputPol = COMP_OUTPUTPOL_NONINVERTED;
  hcomp3.Init.Hysteresis = COMP_HYSTERESIS_NONE;
  hcomp3.Init.BlankingSrce = COMP_BLANKINGSRC_NONE;
  hcomp3.Init.TriggerMode = COMP_TRIGGERMODE_IT_RISING_FALLING;
  if (HAL_COMP_Init(&hcomp3) != HAL_OK)
  {
    Error_Handler();
  }

}

static void MX_COMP6_Init(void)
{

  hcomp6.Instance = COMP6;
  hcomp6.Init.InputPlus = COMP_INPUT_PLUS_IO1;
  hcomp6.Init.InputMinus = COMP_INPUT_MINUS_DAC4_CH2;
  hcomp6.Init.OutputPol = COMP_OUTPUTPOL_NONINVERTED;
  hcomp6.Init.Hysteresis = COMP_HYSTERESIS_NONE;
  hcomp6.Init.BlankingSrce = COMP_BLANKINGSRC_NONE;
  hcomp6.Init.TriggerMode = COMP_TRIGGERMODE_IT_FALLING;
  if (HAL_COMP_Init(&hcomp6) != HAL_OK)
  {
    Error_Handler();
  }

}

static void MX_COMP7_Init(void)
{

  hcomp7.Instance = COMP7;
  hcomp7.Init.InputPlus = COMP_INPUT_PLUS_IO1;
  hcomp7.Init.InputMinus = COMP_INPUT_MINUS_DAC2_CH1;
  hcomp7.Init.OutputPol = COMP_OUTPUTPOL_NONINVERTED;
  hcomp7.Init.Hysteresis = COMP_HYSTERESIS_NONE;
  hcomp7.Init.BlankingSrce = COMP_BLANKINGSRC_NONE;
  hcomp7.Init.TriggerMode = COMP_TRIGGERMODE_NONE;
  if (HAL_COMP_Init(&hcomp7) != HAL_OK)
  {
    Error_Handler();
  }

}

static void MX_DAC2_Init(void)
{

  DAC_ChannelConfTypeDef sConfig = {0};

  /** DAC Initialization
  */
  hdac2.Instance = DAC2;
  if (HAL_DAC_Init(&hdac2) != HAL_OK)
  {
    Error_Handler();
  }

  /** DAC channel OUT1 config
  */
  sConfig.DAC_HighFrequency = DAC_HIGH_FREQUENCY_INTERFACE_MODE_AUTOMATIC;
  sConfig.DAC_DMADoubleDataMode = DISABLE;
  sConfig.DAC_SignedFormat = DISABLE;
  sConfig.DAC_SampleAndHold = DAC_SAMPLEANDHOLD_DISABLE;
  sConfig.DAC_Trigger = DAC_TRIGGER_NONE;
  sConfig.DAC_Trigger2 = DAC_TRIGGER_NONE;
  sConfig.DAC_OutputBuffer = DAC_OUTPUTBUFFER_DISABLE;
  sConfig.DAC_ConnectOnChipPeripheral = DAC_CHIPCONNECT_INTERNAL;
  sConfig.DAC_UserTrimming = DAC_TRIMMING_FACTORY;
  if (HAL_DAC_ConfigChannel(&hdac2, &sConfig, DAC_CHANNEL_1) != HAL_OK)
  {
    Error_Handler();
  }

}

static void MX_DAC3_Init(void)
{

  DAC_ChannelConfTypeDef sConfig = {0};

  /** DAC Initialization
  */
  hdac3.Instance = DAC3;
  if (HAL_DAC_Init(&hdac3) != HAL_OK)
  {
    Error_Handler();
  }

  /** DAC channel OUT1 config
  */
  sConfig.DAC_HighFrequency = DAC_HIGH_FREQUENCY_INTERFACE_MODE_AUTOMATIC;
  sConfig.DAC_DMADoubleDataMode = DISABLE;
  sConfig.DAC_SignedFormat = DISABLE;
  sConfig.DAC_SampleAndHold = DAC_SAMPLEANDHOLD_DISABLE;
  sConfig.DAC_Trigger = DAC_TRIGGER_NONE;
  sConfig.DAC_Trigger2 = DAC_TRIGGER_NONE;
  sConfig.DAC_OutputBuffer = DAC_OUTPUTBUFFER_DISABLE;
  sConfig.DAC_ConnectOnChipPeripheral = DAC_CHIPCONNECT_INTERNAL;
  sConfig.DAC_UserTrimming = DAC_TRIMMING_FACTORY;
  if (HAL_DAC_ConfigChannel(&hdac3, &sConfig, DAC_CHANNEL_1) != HAL_OK)
  {
    Error_Handler();
  }

}

static void MX_DAC4_Init(void)
{

  DAC_ChannelConfTypeDef sConfig = {0};

  /** DAC Initialization
  */
  hdac4.Instance = DAC4;
  if (HAL_DAC_Init(&hdac4) != HAL_OK)
  {
    Error_Handler();
  }

  /** DAC channel OUT2 config
  */
  sConfig.DAC_HighFrequency = DAC_HIGH_FREQUENCY_INTERFACE_MODE_AUTOMATIC;
  sConfig.DAC_DMADoubleDataMode = DISABLE;
  sConfig.DAC_SignedFormat = DISABLE;
  sConfig.DAC_SampleAndHold = DAC_SAMPLEANDHOLD_DISABLE;
  sConfig.DAC_Trigger = DAC_TRIGGER_NONE;
  sConfig.DAC_Trigger2 = DAC_TRIGGER_NONE;
  sConfig.DAC_OutputBuffer = DAC_OUTPUTBUFFER_DISABLE;
  sConfig.DAC_ConnectOnChipPeripheral = DAC_CHIPCONNECT_INTERNAL;
  sConfig.DAC_UserTrimming = DAC_TRIMMING_FACTORY;
  if (HAL_DAC_ConfigChannel(&hdac4, &sConfig, DAC_CHANNEL_2) != HAL_OK)
  {
    Error_Handler();
  }

}

static void MX_FMAC_Init(void)
{

  hfmac.Instance = FMAC;
  if (HAL_FMAC_Init(&hfmac) != HAL_OK)
  {
    Error_Handler();
  }

}

static void MX_HRTIM1_Init(void)
{

  HRTIM_EventCfgTypeDef pEventCfg = {0};
  HRTIM_ADCTriggerCfgTypeDef pADCTriggerCfg = {0};
  HRTIM_TimeBaseCfgTypeDef pTimeBaseCfg = {0};
  HRTIM_TimerCtlTypeDef pTimerCtl = {0};
  HRTIM_TimerCfgTypeDef pTimerCfg = {0};
  HRTIM_CompareCfgTypeDef pCompareCfg = {0};
  HRTIM_OutputCfgTypeDef pOutputCfg = {0};

  hhrtim1.Instance = HRTIM1;
  hhrtim1.Init.HRTIMInterruptResquests = HRTIM_IT_NONE;
  hhrtim1.Init.SyncOptions = HRTIM_SYNCOPTION_NONE;
  if (HAL_HRTIM_Init(&hhrtim1) != HAL_OK)
  {
    Error_Handler();
  }
  if (HAL_HRTIM_DLLCalibrationStart(&hhrtim1, HRTIM_CALIBRATIONRATE_3) != HAL_OK)
  {
    Error_Handler();
  }
  if (HAL_HRTIM_PollForDLLCalibration(&hhrtim1, 10) != HAL_OK)
  {
    Error_Handler();
  }
  if (HAL_HRTIM_EventPrescalerConfig(&hhrtim1, HRTIM_EVENTPRESCALER_DIV1) != HAL_OK)
  {
    Error_Handler();
  }
  pEventCfg.Source = HRTIM_EEV5SRC_COMP7_OUT;
  pEventCfg.Polarity = HRTIM_EVENTPOLARITY_HIGH;
  pEventCfg.Sensitivity = HRTIM_EVENTSENSITIVITY_LEVEL;
  pEventCfg.FastMode = HRTIM_EVENTFASTMODE_ENABLE;
  if (HAL_HRTIM_EventConfig(&hhrtim1, HRTIM_EVENT_5, &pEventCfg) != HAL_OK)
  {
    Error_Handler();
  }
  pADCTriggerCfg.UpdateSource = HRTIM_ADCTRIGGERUPDATE_TIMER_D;
  pADCTriggerCfg.Trigger = HRTIM_ADCTRIGGEREVENT13_TIMERD_PERIOD;
  if (HAL_HRTIM_ADCTriggerConfig(&hhrtim1, HRTIM_ADCTRIGGER_1, &pADCTriggerCfg) != HAL_OK)
  {
    Error_Handler();
  }
  if (HAL_HRTIM_ADCPostScalerConfig(&hhrtim1, HRTIM_ADCTRIGGER_1, 0x0) != HAL_OK)
  {
    Error_Handler();
  }
  pADCTriggerCfg.UpdateSource = HRTIM_ADCTRIGGERUPDATE_TIMER_A;
  pADCTriggerCfg.Trigger = HRTIM_ADCTRIGGEREVENT13_TIMERA_CMP3;
  if (HAL_HRTIM_ADCTriggerConfig(&hhrtim1, HRTIM_ADCTRIGGER_3, &pADCTriggerCfg) != HAL_OK)
  {
    Error_Handler();
  }
  if (HAL_HRTIM_ADCPostScalerConfig(&hhrtim1, HRTIM_ADCTRIGGER_3, 0x0) != HAL_OK)
  {
    Error_Handler();
  }
  pTimeBaseCfg.Period = 0xB115;
  pTimeBaseCfg.RepetitionCounter = 0x00;
  pTimeBaseCfg.PrescalerRatio = HRTIM_PRESCALERRATIO_MUL16;
  pTimeBaseCfg.Mode = HRTIM_MODE_CONTINUOUS;
  if (HAL_HRTIM_TimeBaseConfig(&hhrtim1, HRTIM_TIMERINDEX_TIMER_A, &pTimeBaseCfg) != HAL_OK)
  {
    Error_Handler();
  }
  pTimerCtl.UpDownMode = HRTIM_TIMERUPDOWNMODE_UP;
  pTimerCtl.GreaterCMP3 = HRTIM_TIMERGTCMP3_EQUAL;
  pTimerCtl.GreaterCMP1 = HRTIM_TIMERGTCMP1_EQUAL;
  pTimerCtl.DualChannelDacEnable = HRTIM_TIMER_DCDE_DISABLED;
  if (HAL_HRTIM_WaveformTimerControl(&hhrtim1, HRTIM_TIMERINDEX_TIMER_A, &pTimerCtl) != HAL_OK)
  {
    Error_Handler();
  }
  pTimerCfg.InterruptRequests = HRTIM_TIM_IT_NONE;
  pTimerCfg.DMARequests = HRTIM_TIM_DMA_NONE;
  pTimerCfg.DMASrcAddress = 0x0000;
  pTimerCfg.DMADstAddress = 0x0000;
  pTimerCfg.DMASize = 0x1;
  pTimerCfg.HalfModeEnable = HRTIM_HALFMODE_DISABLED;
  pTimerCfg.InterleavedMode = HRTIM_INTERLEAVED_MODE_DISABLED;
  pTimerCfg.StartOnSync = HRTIM_SYNCSTART_DISABLED;
  pTimerCfg.ResetOnSync = HRTIM_SYNCRESET_DISABLED;
  pTimerCfg.DACSynchro = HRTIM_DACSYNC_NONE;
  pTimerCfg.PreloadEnable = HRTIM_PRELOAD_DISABLED;
  pTimerCfg.UpdateGating = HRTIM_UPDATEGATING_INDEPENDENT;
  pTimerCfg.BurstMode = HRTIM_TIMERBURSTMODE_MAINTAINCLOCK;
  pTimerCfg.RepetitionUpdate = HRTIM_UPDATEONREPETITION_DISABLED;
  pTimerCfg.PushPull = HRTIM_TIMPUSHPULLMODE_DISABLED;
  pTimerCfg.FaultEnable = HRTIM_TIMFAULTENABLE_NONE;
  pTimerCfg.FaultLock = HRTIM_TIMFAULTLOCK_READWRITE;
  pTimerCfg.DeadTimeInsertion = HRTIM_TIMDEADTIMEINSERTION_DISABLED;
  pTimerCfg.DelayedProtectionMode = HRTIM_TIMER_A_B_C_DELAYEDPROTECTION_DISABLED;
  pTimerCfg.UpdateTrigger = HRTIM_TIMUPDATETRIGGER_NONE;
  pTimerCfg.ResetTrigger = HRTIM_TIMRESETTRIGGER_NONE;
  pTimerCfg.ResetUpdate = HRTIM_TIMUPDATEONRESET_DISABLED;
  pTimerCfg.ReSyncUpdate = HRTIM_TIMERESYNC_UPDATE_UNCONDITIONAL;
  if (HAL_HRTIM_WaveformTimerConfig(&hhrtim1, HRTIM_TIMERINDEX_TIMER_A, &pTimerCfg) != HAL_OK)
  {
    Error_Handler();
  }
  pTimerCfg.DelayedProtectionMode = HRTIM_TIMER_D_E_DELAYEDPROTECTION_DISABLED;
  if (HAL_HRTIM_WaveformTimerConfig(&hhrtim1, HRTIM_TIMERINDEX_TIMER_D, &pTimerCfg) != HAL_OK)
  {
    Error_Handler();
  }
  pCompareCfg.CompareValue = 0xFFEF;
  if (HAL_HRTIM_WaveformCompareConfig(&hhrtim1, HRTIM_TIMERINDEX_TIMER_A, HRTIM_COMPAREUNIT_1, &pCompareCfg) != HAL_OK)
  {
    Error_Handler();
  }
  if (HAL_HRTIM_WaveformCompareConfig(&hhrtim1, HRTIM_TIMERINDEX_TIMER_A, HRTIM_COMPAREUNIT_3, &pCompareCfg) != HAL_OK)
  {
    Error_Handler();
  }
  pOutputCfg.Polarity = HRTIM_OUTPUTPOLARITY_HIGH;
  pOutputCfg.SetSource = HRTIM_OUTPUTSET_TIMPER;
  pOutputCfg.ResetSource = HRTIM_OUTPUTRESET_TIMCMP1|HRTIM_OUTPUTSET_EEV_5;
  pOutputCfg.IdleMode = HRTIM_OUTPUTIDLEMODE_NONE;
  pOutputCfg.IdleLevel = HRTIM_OUTPUTIDLELEVEL_INACTIVE;
  pOutputCfg.FaultLevel = HRTIM_OUTPUTFAULTLEVEL_NONE;
  pOutputCfg.ChopperModeEnable = HRTIM_OUTPUTCHOPPERMODE_DISABLED;
  pOutputCfg.BurstModeEntryDelayed = HRTIM_OUTPUTBURSTMODEENTRY_REGULAR;
  if (HAL_HRTIM_WaveformOutputConfig(&hhrtim1, HRTIM_TIMERINDEX_TIMER_A, HRTIM_OUTPUT_TA2, &pOutputCfg) != HAL_OK)
  {
    Error_Handler();
  }
  pTimeBaseCfg.Period = 0xDD5A;
  pTimeBaseCfg.PrescalerRatio = HRTIM_PRESCALERRATIO_MUL2;
  if (HAL_HRTIM_TimeBaseConfig(&hhrtim1, HRTIM_TIMERINDEX_TIMER_D, &pTimeBaseCfg) != HAL_OK)
  {
    Error_Handler();
  }
  if (HAL_HRTIM_WaveformTimerControl(&hhrtim1, HRTIM_TIMERINDEX_TIMER_D, &pTimerCtl) != HAL_OK)
  {
    Error_Handler();
  }
  HAL_HRTIM_MspPostInit(&hhrtim1);

}

static void MX_TIM1_Init(void)
{

  TIM_ClockConfigTypeDef sClockSourceConfig = {0};
  TIM_SlaveConfigTypeDef sSlaveConfig = {0};
  TIM_MasterConfigTypeDef sMasterConfig = {0};
  TIM_IC_InitTypeDef sConfigIC = {0};
  TIM_OC_InitTypeDef sConfigOC = {0};
  TIM_BreakDeadTimeConfigTypeDef sBreakDeadTimeConfig = {0};

  htim1.Instance = TIM1;
  htim1.Init.Prescaler = 0;
  htim1.Init.CounterMode = TIM_COUNTERMODE_UP;
  htim1.Init.Period = 65535;
  htim1.Init.ClockDivision = TIM_CLOCKDIVISION_DIV1;
  htim1.Init.RepetitionCounter = 0;
  htim1.Init.AutoReloadPreload = TIM_AUTORELOAD_PRELOAD_DISABLE;
  if (HAL_TIM_Base_Init(&htim1) != HAL_OK)
  {
    Error_Handler();
  }
  sClockSourceConfig.ClockSource = TIM_CLOCKSOURCE_INTERNAL;
  if (HAL_TIM_ConfigClockSource(&htim1, &sClockSourceConfig) != HAL_OK)
  {
    Error_Handler();
  }
  if (HAL_TIM_IC_Init(&htim1) != HAL_OK)
  {
    Error_Handler();
  }
  if (HAL_TIM_PWM_Init(&htim1) != HAL_OK)
  {
    Error_Handler();
  }
  sSlaveConfig.SlaveMode = TIM_SLAVEMODE_RESET;
  sSlaveConfig.InputTrigger = TIM_TS_ETRF;
  sSlaveConfig.TriggerPolarity = TIM_TRIGGERPOLARITY_NONINVERTED;
  sSlaveConfig.TriggerPrescaler = TIM_TRIGGERPRESCALER_DIV1;
  sSlaveConfig.TriggerFilter = 0;
  if (HAL_TIM_SlaveConfigSynchro(&htim1, &sSlaveConfig) != HAL_OK)
  {
    Error_Handler();
  }
  sMasterConfig.MasterOutputTrigger = TIM_TRGO_OC2REF;
  sMasterConfig.MasterOutputTrigger2 = TIM_TRGO2_RESET;
  sMasterConfig.MasterSlaveMode = TIM_MASTERSLAVEMODE_DISABLE;
  if (HAL_TIMEx_MasterConfigSynchronization(&htim1, &sMasterConfig) != HAL_OK)
  {
    Error_Handler();
  }
  HAL_TIMEx_RemapConfig(&htim1, TIM_TIM1_ETR_COMP1);
  sConfigIC.ICPolarity = TIM_INPUTCHANNELPOLARITY_RISING;
  sConfigIC.ICSelection = TIM_ICSELECTION_DIRECTTI;
  sConfigIC.ICPrescaler = TIM_ICPSC_DIV1;
  sConfigIC.ICFilter = 0;
  if (HAL_TIM_IC_ConfigChannel(&htim1, &sConfigIC, TIM_CHANNEL_1) != HAL_OK)
  {
    Error_Handler();
  }
  if (HAL_TIMEx_TISelection(&htim1, TIM_TIM1_TI1_COMP1, TIM_CHANNEL_1) != HAL_OK)
  {
    Error_Handler();
  }
  sConfigOC.OCMode = TIM_OCMODE_PWM1;
  sConfigOC.Pulse = 0;
  sConfigOC.OCPolarity = TIM_OCPOLARITY_HIGH;
  sConfigOC.OCNPolarity = TIM_OCNPOLARITY_HIGH;
  sConfigOC.OCFastMode = TIM_OCFAST_DISABLE;
  sConfigOC.OCIdleState = TIM_OCIDLESTATE_RESET;
  sConfigOC.OCNIdleState = TIM_OCNIDLESTATE_RESET;
  if (HAL_TIM_PWM_ConfigChannel(&htim1, &sConfigOC, TIM_CHANNEL_2) != HAL_OK)
  {
    Error_Handler();
  }
  sBreakDeadTimeConfig.OffStateRunMode = TIM_OSSR_DISABLE;
  sBreakDeadTimeConfig.OffStateIDLEMode = TIM_OSSI_DISABLE;
  sBreakDeadTimeConfig.LockLevel = TIM_LOCKLEVEL_OFF;
  sBreakDeadTimeConfig.DeadTime = 0;
  sBreakDeadTimeConfig.BreakState = TIM_BREAK_DISABLE;
  sBreakDeadTimeConfig.BreakPolarity = TIM_BREAKPOLARITY_HIGH;
  sBreakDeadTimeConfig.BreakFilter = 0;
  sBreakDeadTimeConfig.BreakAFMode = TIM_BREAK_AFMODE_INPUT;
  sBreakDeadTimeConfig.Break2State = TIM_BREAK2_DISABLE;
  sBreakDeadTimeConfig.Break2Polarity = TIM_BREAK2POLARITY_HIGH;
  sBreakDeadTimeConfig.Break2Filter = 0;
  sBreakDeadTimeConfig.Break2AFMode = TIM_BREAK_AFMODE_INPUT;
  sBreakDeadTimeConfig.AutomaticOutput = TIM_AUTOMATICOUTPUT_DISABLE;
  if (HAL_TIMEx_ConfigBreakDeadTime(&htim1, &sBreakDeadTimeConfig) != HAL_OK)
  {
    Error_Handler();
  }

}

static void MX_TIM3_Init(void)
{

  TIM_ClockConfigTypeDef sClockSourceConfig = {0};
  TIM_MasterConfigTypeDef sMasterConfig = {0};
  TIM_OC_InitTypeDef sConfigOC = {0};

  htim3.Instance = TIM3;
  htim3.Init.Prescaler = 1024;
  htim3.Init.CounterMode = TIM_COUNTERMODE_UP;
  htim3.Init.Period = 255;
  htim3.Init.ClockDivision = TIM_CLOCKDIVISION_DIV1;
  htim3.Init.AutoReloadPreload = TIM_AUTORELOAD_PRELOAD_DISABLE;
  if (HAL_TIM_Base_Init(&htim3) != HAL_OK)
  {
    Error_Handler();
  }
  sClockSourceConfig.ClockSource = TIM_CLOCKSOURCE_INTERNAL;
  if (HAL_TIM_ConfigClockSource(&htim3, &sClockSourceConfig) != HAL_OK)
  {
    Error_Handler();
  }
  if (HAL_TIM_PWM_Init(&htim3) != HAL_OK)
  {
    Error_Handler();
  }
  sMasterConfig.MasterOutputTrigger = TIM_TRGO_RESET;
  sMasterConfig.MasterSlaveMode = TIM_MASTERSLAVEMODE_DISABLE;
  if (HAL_TIMEx_MasterConfigSynchronization(&htim3, &sMasterConfig) != HAL_OK)
  {
    Error_Handler();
  }
  sConfigOC.OCMode = TIM_OCMODE_PWM1;
  sConfigOC.Pulse = 0;
  sConfigOC.OCPolarity = TIM_OCPOLARITY_HIGH;
  sConfigOC.OCFastMode = TIM_OCFAST_DISABLE;
  if (HAL_TIM_PWM_ConfigChannel(&htim3, &sConfigOC, TIM_CHANNEL_1) != HAL_OK)
  {
    Error_Handler();
  }
  if (HAL_TIM_PWM_ConfigChannel(&htim3, &sConfigOC, TIM_CHANNEL_2) != HAL_OK)
  {
    Error_Handler();
  }
  if (HAL_TIM_PWM_ConfigChannel(&htim3, &sConfigOC, TIM_CHANNEL_3) != HAL_OK)
  {
    Error_Handler();
  }
  HAL_TIM_MspPostInit(&htim3);

}

static void MX_TIM6_Init(void)
{

  TIM_MasterConfigTypeDef sMasterConfig = {0};

  htim6.Instance = TIM6;
  htim6.Init.Prescaler = 170;
  htim6.Init.CounterMode = TIM_COUNTERMODE_UP;
  htim6.Init.Period = 10000;
  htim6.Init.AutoReloadPreload = TIM_AUTORELOAD_PRELOAD_DISABLE;
  if (HAL_TIM_Base_Init(&htim6) != HAL_OK)
  {
    Error_Handler();
  }
  sMasterConfig.MasterOutputTrigger = TIM_TRGO_UPDATE;
  sMasterConfig.MasterSlaveMode = TIM_MASTERSLAVEMODE_DISABLE;
  if (HAL_TIMEx_MasterConfigSynchronization(&htim6, &sMasterConfig) != HAL_OK)
  {
    Error_Handler();
  }

}

static void MX_TIM7_Init(void)
{

  TIM_MasterConfigTypeDef sMasterConfig = {0};

  htim7.Instance = TIM7;
  htim7.Init.Prescaler = 17000;
  htim7.Init.CounterMode = TIM_COUNTERMODE_UP;
  htim7.Init.Period = 5000;
  htim7.Init.AutoReloadPreload = TIM_AUTORELOAD_PRELOAD_DISABLE;
  if (HAL_TIM_Base_Init(&htim7) != HAL_OK)
  {
    Error_Handler();
  }
  sMasterConfig.MasterOutputTrigger = TIM_TRGO_UPDATE;
  sMasterConfig.MasterSlaveMode = TIM_MASTERSLAVEMODE_DISABLE;
  if (HAL_TIMEx_MasterConfigSynchronization(&htim7, &sMasterConfig) != HAL_OK)
  {
    Error_Handler();
  }

}

static void MX_TIM8_Init(void)
{

  TIM_ClockConfigTypeDef sClockSourceConfig = {0};
  TIM_SlaveConfigTypeDef sSlaveConfig = {0};
  TIM_MasterConfigTypeDef sMasterConfig = {0};
  TIM_OC_InitTypeDef sConfigOC = {0};
  TIM_BreakDeadTimeConfigTypeDef sBreakDeadTimeConfig = {0};

  htim8.Instance = TIM8;
  htim8.Init.Prescaler = 0;
  htim8.Init.CounterMode = TIM_COUNTERMODE_UP;
  htim8.Init.Period = 65535;
  htim8.Init.ClockDivision = TIM_CLOCKDIVISION_DIV1;
  htim8.Init.RepetitionCounter = 0;
  htim8.Init.AutoReloadPreload = TIM_AUTORELOAD_PRELOAD_DISABLE;
  if (HAL_TIM_Base_Init(&htim8) != HAL_OK)
  {
    Error_Handler();
  }
  sClockSourceConfig.ClockSource = TIM_CLOCKSOURCE_INTERNAL;
  if (HAL_TIM_ConfigClockSource(&htim8, &sClockSourceConfig) != HAL_OK)
  {
    Error_Handler();
  }
  if (HAL_TIM_PWM_Init(&htim8) != HAL_OK)
  {
    Error_Handler();
  }
  sSlaveConfig.SlaveMode = TIM_SLAVEMODE_RESET;
  sSlaveConfig.InputTrigger = TIM_TS_ITR0;
  if (HAL_TIM_SlaveConfigSynchro(&htim8, &sSlaveConfig) != HAL_OK)
  {
    Error_Handler();
  }
  sMasterConfig.MasterOutputTrigger = TIM_TRGO_RESET;
  sMasterConfig.MasterOutputTrigger2 = TIM_TRGO2_RESET;
  sMasterConfig.MasterSlaveMode = TIM_MASTERSLAVEMODE_DISABLE;
  if (HAL_TIMEx_MasterConfigSynchronization(&htim8, &sMasterConfig) != HAL_OK)
  {
    Error_Handler();
  }
  sConfigOC.OCMode = TIM_OCMODE_PWM1;
  sConfigOC.Pulse = 0;
  sConfigOC.OCPolarity = TIM_OCPOLARITY_HIGH;
  sConfigOC.OCNPolarity = TIM_OCNPOLARITY_HIGH;
  sConfigOC.OCFastMode = TIM_OCFAST_DISABLE;
  sConfigOC.OCIdleState = TIM_OCIDLESTATE_RESET;
  sConfigOC.OCNIdleState = TIM_OCNIDLESTATE_RESET;
  if (HAL_TIM_PWM_ConfigChannel(&htim8, &sConfigOC, TIM_CHANNEL_3) != HAL_OK)
  {
    Error_Handler();
  }
  sBreakDeadTimeConfig.OffStateRunMode = TIM_OSSR_DISABLE;
  sBreakDeadTimeConfig.OffStateIDLEMode = TIM_OSSI_DISABLE;
  sBreakDeadTimeConfig.LockLevel = TIM_LOCKLEVEL_OFF;
  sBreakDeadTimeConfig.DeadTime = 9;
  sBreakDeadTimeConfig.BreakState = TIM_BREAK_DISABLE;
  sBreakDeadTimeConfig.BreakPolarity = TIM_BREAKPOLARITY_HIGH;
  sBreakDeadTimeConfig.BreakFilter = 0;
  sBreakDeadTimeConfig.BreakAFMode = TIM_BREAK_AFMODE_INPUT;
  sBreakDeadTimeConfig.Break2State = TIM_BREAK2_DISABLE;
  sBreakDeadTimeConfig.Break2Polarity = TIM_BREAK2POLARITY_HIGH;
  sBreakDeadTimeConfig.Break2Filter = 0;
  sBreakDeadTimeConfig.Break2AFMode = TIM_BREAK_AFMODE_INPUT;
  sBreakDeadTimeConfig.AutomaticOutput = TIM_AUTOMATICOUTPUT_DISABLE;
  if (HAL_TIMEx_ConfigBreakDeadTime(&htim8, &sBreakDeadTimeConfig) != HAL_OK)
  {
    Error_Handler();
  }
  HAL_TIM_MspPostInit(&htim8);

}

static void MX_TIM15_Init(void)
{

  TIM_MasterConfigTypeDef sMasterConfig = {0};
  TIM_OC_InitTypeDef sConfigOC = {0};
  TIM_BreakDeadTimeConfigTypeDef sBreakDeadTimeConfig = {0};

  htim15.Instance = TIM15;
  htim15.Init.Prescaler = 0;
  htim15.Init.CounterMode = TIM_COUNTERMODE_UP;
  htim15.Init.Period = 65535;
  htim15.Init.ClockDivision = TIM_CLOCKDIVISION_DIV1;
  htim15.Init.RepetitionCounter = 0;
  htim15.Init.AutoReloadPreload = TIM_AUTORELOAD_PRELOAD_DISABLE;
  if (HAL_TIM_PWM_Init(&htim15) != HAL_OK)
  {
    Error_Handler();
  }
  sMasterConfig.MasterOutputTrigger = TIM_TRGO_RESET;
  sMasterConfig.MasterSlaveMode = TIM_MASTERSLAVEMODE_DISABLE;
  if (HAL_TIMEx_MasterConfigSynchronization(&htim15, &sMasterConfig) != HAL_OK)
  {
    Error_Handler();
  }
  sConfigOC.OCMode = TIM_OCMODE_PWM1;
  sConfigOC.Pulse = 0;
  sConfigOC.OCPolarity = TIM_OCPOLARITY_HIGH;
  sConfigOC.OCNPolarity = TIM_OCNPOLARITY_HIGH;
  sConfigOC.OCFastMode = TIM_OCFAST_DISABLE;
  sConfigOC.OCIdleState = TIM_OCIDLESTATE_RESET;
  sConfigOC.OCNIdleState = TIM_OCNIDLESTATE_RESET;
  if (HAL_TIM_PWM_ConfigChannel(&htim15, &sConfigOC, TIM_CHANNEL_2) != HAL_OK)
  {
    Error_Handler();
  }
  sBreakDeadTimeConfig.OffStateRunMode = TIM_OSSR_DISABLE;
  sBreakDeadTimeConfig.OffStateIDLEMode = TIM_OSSI_DISABLE;
  sBreakDeadTimeConfig.LockLevel = TIM_LOCKLEVEL_OFF;
  sBreakDeadTimeConfig.DeadTime = 0;
  sBreakDeadTimeConfig.BreakState = TIM_BREAK_DISABLE;
  sBreakDeadTimeConfig.BreakPolarity = TIM_BREAKPOLARITY_HIGH;
  sBreakDeadTimeConfig.BreakFilter = 0;
  sBreakDeadTimeConfig.AutomaticOutput = TIM_AUTOMATICOUTPUT_DISABLE;
  if (HAL_TIMEx_ConfigBreakDeadTime(&htim15, &sBreakDeadTimeConfig) != HAL_OK)
  {
    Error_Handler();
  }
  HAL_TIM_MspPostInit(&htim15);

}

static void MX_TIM20_Init(void)
{

  TIM_ClockConfigTypeDef sClockSourceConfig = {0};
  TIM_SlaveConfigTypeDef sSlaveConfig = {0};
  TIM_MasterConfigTypeDef sMasterConfig = {0};
  TIM_OC_InitTypeDef sConfigOC = {0};
  TIM_BreakDeadTimeConfigTypeDef sBreakDeadTimeConfig = {0};

  htim20.Instance = TIM20;
  htim20.Init.Prescaler = 170;
  htim20.Init.CounterMode = TIM_COUNTERMODE_UP;
  htim20.Init.Period = 65535;
  htim20.Init.ClockDivision = TIM_CLOCKDIVISION_DIV1;
  htim20.Init.RepetitionCounter = 0;
  htim20.Init.AutoReloadPreload = TIM_AUTORELOAD_PRELOAD_DISABLE;
  if (HAL_TIM_Base_Init(&htim20) != HAL_OK)
  {
    Error_Handler();
  }
  sClockSourceConfig.ClockSource = TIM_CLOCKSOURCE_INTERNAL;
  if (HAL_TIM_ConfigClockSource(&htim20, &sClockSourceConfig) != HAL_OK)
  {
    Error_Handler();
  }
  if (HAL_TIM_PWM_Init(&htim20) != HAL_OK)
  {
    Error_Handler();
  }
  if (HAL_TIM_OnePulse_Init(&htim20, TIM_OPMODE_SINGLE) != HAL_OK)
  {
    Error_Handler();
  }
  sSlaveConfig.SlaveMode = TIM_SLAVEMODE_COMBINED_RESETTRIGGER;
  sSlaveConfig.InputTrigger = TIM_TS_ETRF;
  sSlaveConfig.TriggerPolarity = TIM_TRIGGERPOLARITY_NONINVERTED;
  sSlaveConfig.TriggerPrescaler = TIM_TRIGGERPRESCALER_DIV1;
  sSlaveConfig.TriggerFilter = 0;
  if (HAL_TIM_SlaveConfigSynchro(&htim20, &sSlaveConfig) != HAL_OK)
  {
    Error_Handler();
  }
  sMasterConfig.MasterOutputTrigger = TIM_TRGO_RESET;
  sMasterConfig.MasterOutputTrigger2 = TIM_TRGO2_RESET;
  sMasterConfig.MasterSlaveMode = TIM_MASTERSLAVEMODE_DISABLE;
  if (HAL_TIMEx_MasterConfigSynchronization(&htim20, &sMasterConfig) != HAL_OK)
  {
    Error_Handler();
  }
  HAL_TIMEx_RemapConfig(&htim20, TIM_TIM20_ETR_COMP6);
  sConfigOC.OCMode = TIM_OCMODE_PWM2;
  sConfigOC.Pulse = 0;
  sConfigOC.OCPolarity = TIM_OCPOLARITY_HIGH;
  sConfigOC.OCNPolarity = TIM_OCNPOLARITY_HIGH;
  sConfigOC.OCFastMode = TIM_OCFAST_DISABLE;
  sConfigOC.OCIdleState = TIM_OCIDLESTATE_RESET;
  sConfigOC.OCNIdleState = TIM_OCNIDLESTATE_RESET;
  if (HAL_TIM_PWM_ConfigChannel(&htim20, &sConfigOC, TIM_CHANNEL_1) != HAL_OK)
  {
    Error_Handler();
  }
  sBreakDeadTimeConfig.OffStateRunMode = TIM_OSSR_DISABLE;
  sBreakDeadTimeConfig.OffStateIDLEMode = TIM_OSSI_DISABLE;
  sBreakDeadTimeConfig.LockLevel = TIM_LOCKLEVEL_OFF;
  sBreakDeadTimeConfig.DeadTime = 0;
  sBreakDeadTimeConfig.BreakState = TIM_BREAK_DISABLE;
  sBreakDeadTimeConfig.BreakPolarity = TIM_BREAKPOLARITY_HIGH;
  sBreakDeadTimeConfig.BreakFilter = 0;
  sBreakDeadTimeConfig.BreakAFMode = TIM_BREAK_AFMODE_INPUT;
  sBreakDeadTimeConfig.Break2State = TIM_BREAK2_DISABLE;
  sBreakDeadTimeConfig.Break2Polarity = TIM_BREAK2POLARITY_HIGH;
  sBreakDeadTimeConfig.Break2Filter = 0;
  sBreakDeadTimeConfig.Break2AFMode = TIM_BREAK_AFMODE_INPUT;
  sBreakDeadTimeConfig.AutomaticOutput = TIM_AUTOMATICOUTPUT_DISABLE;
  if (HAL_TIMEx_ConfigBreakDeadTime(&htim20, &sBreakDeadTimeConfig) != HAL_OK)
  {
    Error_Handler();
  }
  HAL_TIM_MspPostInit(&htim20);

}

static void MX_USART3_UART_Init(void)
{

  huart3.Instance = USART3;
  huart3.Init.BaudRate = 115200;
  huart3.Init.WordLength = UART_WORDLENGTH_8B;
  huart3.Init.StopBits = UART_STOPBITS_1;
  huart3.Init.Parity = UART_PARITY_NONE;
  huart3.Init.Mode = UART_MODE_TX_RX;
  huart3.Init.HwFlowCtl = UART_HWCONTROL_NONE;
  huart3.Init.OverSampling = UART_OVERSAMPLING_16;
  huart3.Init.OneBitSampling = UART_ONE_BIT_SAMPLE_DISABLE;
  huart3.Init.ClockPrescaler = UART_PRESCALER_DIV1;
  huart3.AdvancedInit.AdvFeatureInit = UART_ADVFEATURE_NO_INIT;
  if (HAL_UART_Init(&huart3) != HAL_OK)
  {
    Error_Handler();
  }
  if (HAL_UARTEx_SetTxFifoThreshold(&huart3, UART_TXFIFO_THRESHOLD_1_8) != HAL_OK)
  {
    Error_Handler();
  }
  if (HAL_UARTEx_SetRxFifoThreshold(&huart3, UART_RXFIFO_THRESHOLD_1_8) != HAL_OK)
  {
    Error_Handler();
  }
  if (HAL_UARTEx_DisableFifoMode(&huart3) != HAL_OK)
  {
    Error_Handler();
  }

}

static void MX_DMA_Init(void)
{

  /* DMA controller clock enable */
  __HAL_RCC_DMAMUX1_CLK_ENABLE();
  __HAL_RCC_DMA1_CLK_ENABLE();
  __HAL_RCC_DMA2_CLK_ENABLE();

  /* DMA interrupt init */
  /* DMA1_Channel1_IRQn interrupt configuration */
  HAL_NVIC_SetPriority(DMA1_Channel1_IRQn, 0, 0);
  HAL_NVIC_EnableIRQ(DMA1_Channel1_IRQn);
  /* DMA1_Channel2_IRQn interrupt configuration */
  HAL_NVIC_SetPriority(DMA1_Channel2_IRQn, 0, 0);
  HAL_NVIC_EnableIRQ(DMA1_Channel2_IRQn);
  /* DMA2_Channel1_IRQn interrupt configuration */
  HAL_NVIC_SetPriority(DMA2_Channel1_IRQn, 0, 0);
  HAL_NVIC_EnableIRQ(DMA2_Channel1_IRQn);
  /* DMA2_Channel2_IRQn interrupt configuration */
  HAL_NVIC_SetPriority(DMA2_Channel2_IRQn, 0, 0);
  HAL_NVIC_EnableIRQ(DMA2_Channel2_IRQn);

}

static void MX_GPIO_Init(void)
{
  GPIO_InitTypeDef GPIO_InitStruct = {0};

  /* GPIO Ports Clock Enable */
  __HAL_RCC_GPIOF_CLK_ENABLE();
  __HAL_RCC_GPIOA_CLK_ENABLE();
  __HAL_RCC_GPIOB_CLK_ENABLE();

  /*Configure GPIO pin Output Level */
  HAL_GPIO_WritePin(GPIOB, FAN_EN_Pin|GDT2_DIS_Pin|GDT1_DIS_Pin, GPIO_PIN_RESET);

  /*Configure GPIO pin : INT_Pin */
  GPIO_InitStruct.Pin = INT_Pin;
  GPIO_InitStruct.Mode = GPIO_MODE_IT_RISING_FALLING;
  GPIO_InitStruct.Pull = GPIO_NOPULL;
  HAL_GPIO_Init(INT_GPIO_Port, &GPIO_InitStruct);

  /*Configure GPIO pin : FAN_EN_Pin */
  GPIO_InitStruct.Pin = FAN_EN_Pin;
  GPIO_InitStruct.Mode = GPIO_MODE_OUTPUT_PP;
  GPIO_InitStruct.Pull = GPIO_NOPULL;
  GPIO_InitStruct.Speed = GPIO_SPEED_FREQ_LOW;
  HAL_GPIO_Init(FAN_EN_GPIO_Port, &GPIO_InitStruct);

  /*Configure GPIO pin : MODE_IN_Pin */
  GPIO_InitStruct.Pin = MODE_IN_Pin;
  GPIO_InitStruct.Mode = GPIO_MODE_INPUT;
  GPIO_InitStruct.Pull = GPIO_NOPULL;
  HAL_GPIO_Init(MODE_IN_GPIO_Port, &GPIO_InitStruct);

  /*Configure GPIO pins : GDT2_DIS_Pin GDT1_DIS_Pin */
  GPIO_InitStruct.Pin = GDT2_DIS_Pin|GDT1_DIS_Pin;
  GPIO_InitStruct.Mode = GPIO_MODE_OUTPUT_PP;
  GPIO_InitStruct.Pull = GPIO_NOPULL;
  GPIO_InitStruct.Speed = GPIO_SPEED_FREQ_VERY_HIGH;
  HAL_GPIO_Init(GPIOB, &GPIO_InitStruct);

  /* EXTI interrupt init*/
  HAL_NVIC_SetPriority(EXTI9_5_IRQn, 0, 0);
  HAL_NVIC_EnableIRQ(EXTI9_5_IRQn);

}

void Error_Handler(void)
{
  __disable_irq();
  while (1)
  {
  }
}
